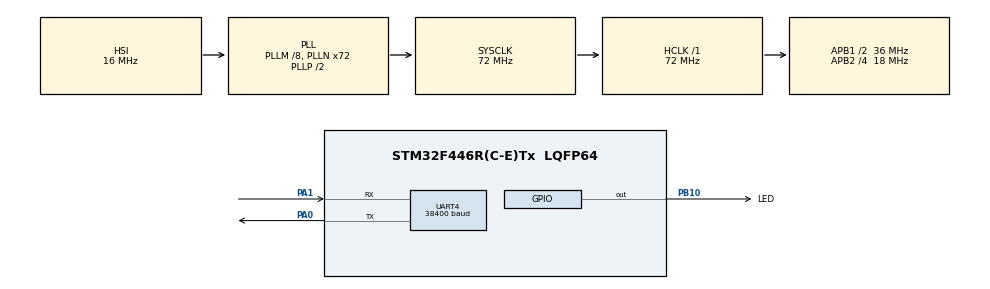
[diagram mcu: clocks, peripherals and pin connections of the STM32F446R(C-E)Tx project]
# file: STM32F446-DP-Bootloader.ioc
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Mcu.Family=STM32F4
Mcu.Name=STM32F446R(C-E)Tx
Mcu.Package=LQFP64
NVIC.PriorityGroup=NVIC_PRIORITYGROUP_4
PA0-WKUP.Mode=Asynchronous
PA0-WKUP.Signal=UART4_TX
PA1.Mode=Asynchronous
PA1.Signal=UART4_RX
PA13.Mode=Serial_Wire
PA13.Signal=SYS_JTMS-SWDIO
PA14.Mode=Serial_Wire
PA14.Signal=SYS_JTCK-SWCLK
PB10.GPIO_Label=LED
PB10.Signal=GPIO_Output
ProjectManager.HeapSize=0x200
ProjectManager.StackSize=0x400
ProjectManager.TargetToolchain=STM32CubeIDE
RCC.AHBFreq_Value=72000000
RCC.APB1CLKDivider=RCC_HCLK_DIV2
RCC.APB1Freq_Value=36000000
RCC.APB1TimFreq_Value=72000000
RCC.APB2CLKDivider=RCC_HCLK_DIV4
RCC.APB2Freq_Value=18000000
RCC.APB2TimFreq_Value=36000000
RCC.CortexFreq_Value=72000000
RCC.HCLKFreq_Value=72000000
RCC.PLLM=8
RCC.PLLN=72
RCC.SYSCLKFreq_VALUE=72000000
RCC.SYSCLKSource=RCC_SYSCLKSOURCE_PLLCLK
RCC.USBFreq_Value=72000000
RCC.VCOOutputFreq_Value=144000000
UART4.BaudRate=38400
UART4.VirtualMode=Asynchronous
board=custom

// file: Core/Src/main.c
/* USER CODE BEGIN Header */
/**
  ******************************************************************************
  * @file           : main.c
  * @brief          : Main program body
  ******************************************************************************
  * @attention
  *
  * Copyright (c) 2022 STMicroelectronics.
  * All rights reserved.
  *
  * This software is licensed under terms that can be found in the LICENSE file
  * in the root directory of this software component.
  * If no LICENSE file comes with this software, it is provided AS-IS.
  *
  ******************************************************************************
  */
/* USER CODE END Header */
#include "main.h"

/* USER CODE BEGIN Includes */
#include <stdio.h>
#include <string.h>
#include <stdbool.h>

#include "iap.h"
#include "flash.h"
/* USER CODE END Includes */

/* USER CODE BEGIN PD */
#define MSG_LEN 100
#define UART_WAIT ((uint16_t)1000u)
#define STRUCT_ADDRERSS 0x08004800u
/* USER CODE END PD */

 UART_HandleTypeDef huart4;

void SystemClock_Config(void);
static void MX_GPIO_Init(void);
static void MX_UART4_Init(void);

int main(void)
{
  /* USER CODE BEGIN 1 */
	uint32_t initBL;
	uint32_t *p_BL = &initBL;
	flash_read((uint32_t)0x08004000u, p_BL, 1);
	IAPSTRUCT iapStruct;
	uint32_t numofwords = 12;
	uint32_t *p_iapStruct = (uint32_t *)&iapStruct;
	IAPSTRUCT readStruct;
	uint32_t *p_readStruct = (uint32_t *)&readStruct;
  /* USER CODE END 1 */

  /* MCU Configuration--------------------------------------------------------*/

  /* Reset of all peripherals, Initializes the Flash interface and the Systick. */
  HAL_Init();

  /* Configure the system clock */
  SystemClock_Config();

  /* Initialize all configured peripherals */
  MX_GPIO_Init();
  MX_UART4_Init();
  /* USER CODE BEGIN 2 */
  /**	Name:	Bootloader initialization and BL jump to app
     * 	Info:	Firstly, decide below, what is the first address to jump to.
 	* 			Secondly, upload first functional app to that location.
     * 			Thirdly, upload the bootloader, First run setups the IAP structure tree.
     * 			Fourthly, reset the MCU.
     * 			Lastly, from now on the BL after MCU reset looks to the iapStruct (can change in the APP)
     *					and jumps to the new application in ADDRESS TO JUMP position
     */
   if (initBL != 1)
   {
 	/* First structure initialization */
 	iapStruct.BOOT_VALIDITY = 0x01u;
 	iapStruct.ADDRESS_APP_1_START = (uint32_t)0x08010000u;
 	iapStruct.ADDRESS_APP_2_START = (uint32_t)0x08040000u;
 	iapStruct.ADDRESS_APP_1_END = (uint32_t)0x0803FFFFu;
 	iapStruct.ADDRESS_APP_2_END = (uint32_t)0x0807FFFFu;
 	iapStruct.ADDRESS_APP_END = (uint32_t)0x0807FFFFu;
 	iapStruct.error.APP_1 = (uint32_t)0x00u;
 	iapStruct.error.APP_2 = (uint32_t)0x00u;
 	iapStruct.tested.APP_1 = (uint32_t)0x01u;
 	iapStruct.tested.APP_2 = (uint32_t)0x01u;
 	iapStruct.app_1_version.MAJOR = (uint32_t)0x00u;
 	iapStruct.app_1_version.MINOR = (uint32_t)0x00u;
 	iapStruct.app_2_version.MAJOR = (uint32_t)0x00u;
 	iapStruct.app_2_version.MINOR = (uint32_t)0x00u;
 	iapStruct.bl_version.MAJOR = (uint32_t)0x00u;
 	iapStruct.bl_version.MINOR = (uint32_t)0x00u;
 	iapStruct.ADDRESS_TO_JUMP = iapStruct.ADDRESS_APP_1_START;

 	flash_write((uint32_t)STRUCT_ADDRERSS, p_iapStruct, numofwords);
 	initBL = 1;
 	flash_write((uint32_t)0x08004000u, p_BL, 1);
   }
   else
   {
 	flash_read((uint32_t)STRUCT_ADDRERSS, p_readStruct, numofwords);
 	printf("Starting the Bootloader (%d.%d)\n\r", readStruct.bl_version.MAJOR, readStruct.bl_version.MINOR);
 	HAL_GPIO_WritePin(GPIOB, GPIO_PIN_10, GPIO_PIN_SET);
 	HAL_Delay(2000u);
 	if ((readStruct.BOOT_VALIDITY == 1) &&
 			(((readStruct.tested.APP_2 == 1) && (readStruct.error.APP_2 == 0)) ||
 					((readStruct.tested.APP_1 == 1) && (readStruct.error.APP_1 == 0))))
 	{
 		printf("%lx\n\r",readStruct.ADDRESS_TO_JUMP);
 		flash_jump_to_app(readStruct.ADDRESS_TO_JUMP);
 	}
   }
  /* USER CODE END 2 */

  /* Infinite loop */
  /* USER CODE BEGIN WHILE */
  while (1)
  {
	  HAL_GPIO_TogglePin(GPIOB, LED_Pin);
	  HAL_Delay(1000U);
    /* USER CODE END WHILE */

  }
}

void SystemClock_Config(void)
{
  RCC_OscInitTypeDef RCC_OscInitStruct = {0};
  RCC_ClkInitTypeDef RCC_ClkInitStruct = {0};

  /** Configure the main internal regulator output voltage
  */
  __HAL_RCC_PWR_CLK_ENABLE();
  __HAL_PWR_VOLTAGESCALING_CONFIG(PWR_REGULATOR_VOLTAGE_SCALE3);

  /** Initializes the RCC Oscillators according to the specified parameters
  * in the RCC_OscInitTypeDef structure.
  */
  RCC_OscInitStruct.OscillatorType = RCC_OSCILLATORTYPE_HSI;
  RCC_OscInitStruct.HSIState = RCC_HSI_ON;
  RCC_OscInitStruct.HSICalibrationValue = RCC_HSICALIBRATION_DEFAULT;
  RCC_OscInitStruct.PLL.PLLState = RCC_PLL_ON;
  RCC_OscInitStruct.PLL.PLLSource = RCC_PLLSOURCE_HSI;
  RCC_OscInitStruct.PLL.PLLM = 8;
  RCC_OscInitStruct.PLL.PLLN = 72;
  RCC_OscInitStruct.PLL.PLLP = RCC_PLLP_DIV2;
  RCC_OscInitStruct.PLL.PLLQ = 2;
  RCC_OscInitStruct.PLL.PLLR = 2;
  if (HAL_RCC_OscConfig(&RCC_OscInitStruct) != HAL_OK)
  {
    Error_Handler();
  }

  /** Initializes the CPU, AHB and APB buses clocks
  */
  RCC_ClkInitStruct.ClockType = RCC_CLOCKTYPE_HCLK|RCC_CLOCKTYPE_SYSCLK
                              |RCC_CLOCKTYPE_PCLK1|RCC_CLOCKTYPE_PCLK2;
  RCC_ClkInitStruct.SYSCLKSource = RCC_SYSCLKSOURCE_PLLCLK;
  RCC_ClkInitStruct.AHBCLKDivider = RCC_SYSCLK_DIV1;
  RCC_ClkInitStruct.APB1CLKDivider = RCC_HCLK_DIV2;
  RCC_ClkInitStruct.APB2CLKDivider = RCC_HCLK_DIV4;

  if (HAL_RCC_ClockConfig(&RCC_ClkInitStruct, FLASH_LATENCY_2) != HAL_OK)
  {
    Error_Handler();
  }
}

static void MX_UART4_Init(void)
{

  huart4.Instance = UART4;
  huart4.Init.BaudRate = 38400;
  huart4.Init.WordLength = UART_WORDLENGTH_8B;
  huart4.Init.StopBits = UART_STOPBITS_1;
  huart4.Init.Parity = UART_PARITY_NONE;
  huart4.Init.Mode = UART_MODE_TX_RX;
  huart4.Init.HwFlowCtl = UART_HWCONTROL_NONE;
  huart4.Init.OverSampling = UART_OVERSAMPLING_16;
  if (HAL_UART_Init(&huart4) != HAL_OK)
  {
    Error_Handler();
  }

}

static void MX_GPIO_Init(void)
{
  GPIO_InitTypeDef GPIO_InitStruct = {0};

  /* GPIO Ports Clock Enable */
  __HAL_RCC_GPIOA_CLK_ENABLE();
  __HAL_RCC_GPIOB_CLK_ENABLE();

  /*Configure GPIO pin Output Level */
  HAL_GPIO_WritePin(LED_GPIO_Port, LED_Pin, GPIO_PIN_RESET);

  /*Configure GPIO pin : LED_Pin */
  GPIO_InitStruct.Pin = LED_Pin;
  GPIO_InitStruct.Mode = GPIO_MODE_OUTPUT_PP;
  GPIO_InitStruct.Pull = GPIO_NOPULL;
  GPIO_InitStruct.Speed = GPIO_SPEED_FREQ_LOW;
  HAL_GPIO_Init(LED_GPIO_Port, &GPIO_InitStruct);

}

/* USER CODE BEGIN 4 */
/**
  * @brief Print the characters to UART (printf).
  * @retval int
  */
#ifdef __GNUC__
  /* With GCC, small printf (option LD Linker->Libraries->Small printf
     set to 'Yes') calls __io_putchar() */
int __io_putchar(int ch)
#else
int fputc(int ch, FILE *f)
#endif /* __GNUC__ */
{
  /* Place your implementation of fputc here */
  /* e.g. write a character to the UART3 and Loop until the end of transmission */
  HAL_UART_Transmit(&huart4, (uint8_t *)&ch, 1, HAL_MAX_DELAY);
  return ch;
}
/* USER CODE END 4 */

void Error_Handler(void)
{
  __disable_irq();
  while (1)
  {
  }
}
